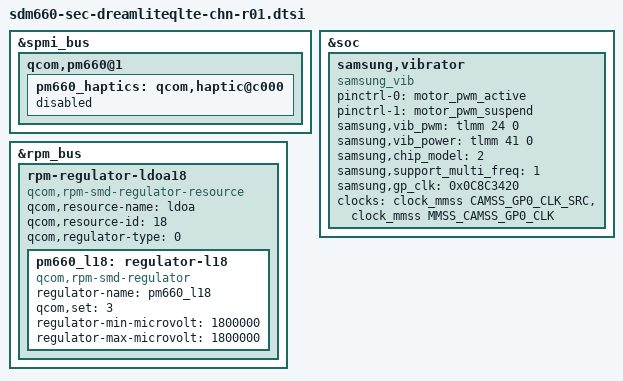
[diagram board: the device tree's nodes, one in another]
/*
 * Copyright (c) 2017, The Linux Foundation. All rights reserved.
 *
 * This program is free software; you can redistribute it and/or modify
 * it under the terms of the GNU General Public License version 2 and
 * only version 2 as published by the Free Software Foundation.
 *
 * This program is distributed in the hope that it will be useful,
 * but WITHOUT ANY WARRANTY; without even the implied warranty of
 * MERCHANTABILITY or FITNESS FOR A PARTICULAR PURPOSE.  See the
 * GNU General Public License for more details.
 */




#include "sdm660-sec-dreamliteqlte-common.dtsi"

&spmi_bus {
	qcom,pm660@1 {
	        pm660_haptics: qcom,haptic@c000 {
                        status = "disabled";
	        };
	};
};

&soc {
	samsung,vibrator {
		compatible = "samsung_vib";
		pinctrl-names = "tlmm_motor_active","tlmm_motor_suspend";
		pinctrl-0 = <&motor_pwm_active>;
		pinctrl-1 = <&motor_pwm_suspend>;
		samsung,vib_pwm = <&tlmm 24 0>;
		samsung,vib_power = <&tlmm 41 0>;
		samsung,chip_model = <2>;        // using sm5720 driver
		samsung,support_multi_freq = <1>;
		samsung,gp_clk = <0x0C8C3420>;   // Address of GP0 clock base
                clocks = <&clock_mmss CAMSS_GP0_CLK_SRC>, 
                <&clock_mmss MMSS_CAMSS_GP0_CLK>; 
                clock-names = "motor-pwm-clk", "motor-pwm-clk-cbcr"; 
		status = "ok";
	};
};

&rpm_bus {
	rpm-regulator-ldoa18 {
		compatible = "qcom,rpm-smd-regulator-resource";
		qcom,resource-name = "ldoa";
		qcom,resource-id = <18>;
		qcom,regulator-type = <0>;
		status = "okay";
	
		pm660_l18: regulator-l18 {
			compatible = "qcom,rpm-smd-regulator";
			regulator-name = "pm660_l18";
			qcom,set = <3>;
			regulator-min-microvolt = <1800000>;
			regulator-max-microvolt = <1800000>;
			status = "okay";
		};
	};
};
